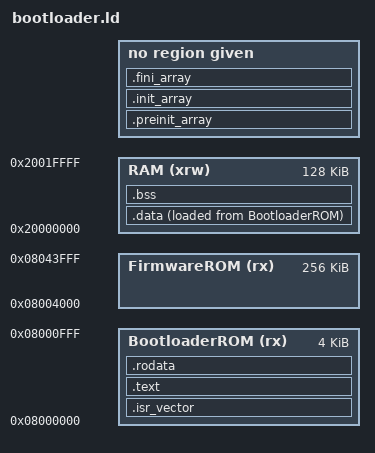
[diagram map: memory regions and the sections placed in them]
ENTRY(Reset_Handler)
_estack = ORIGIN(RAM) + LENGTH(RAM);

MEMORY
{
  RAM            (xrw) : ORIGIN = 0x20000000,  LENGTH = 128K
  BootloaderROM  (rx)  : ORIGIN = 0x8000000,   LENGTH = 4K
  FirmwareROM    (rx)  : ORIGIN = 0x8004000,   LENGTH = 256K
}

_sfirmware = ORIGIN(FirmwareROM);

SECTIONS
{
  .isr_vector :
  {
    . = ALIGN(4);
    KEEP(*(.isr_vector))
    . = ALIGN(4);
  } >BootloaderROM

  .text :
  {
    . = ALIGN(4);
    *(.text)
    *(.text*)

    KEEP (*(.init))
    KEEP (*(.fini))

    . = ALIGN(4);
    _etext = .;
  } >BootloaderROM

  .rodata :
  {
    . = ALIGN(4);

    *(.rodata)
    *(.rodata*)

    . = ALIGN(4);
  } >BootloaderROM


  .preinit_array     :
  {
    . = ALIGN(4);
    PROVIDE_HIDDEN (__preinit_array_start = .);
    KEEP (*(.preinit_array*))
    PROVIDE_HIDDEN (__preinit_array_end = .);
    . = ALIGN(4);
  } >FLASH

  .init_array :
  {
    . = ALIGN(4);
    PROVIDE_HIDDEN (__init_array_start = .);
    KEEP (*(SORT(.init_array.*)))
    KEEP (*(.init_array*))
    PROVIDE_HIDDEN (__init_array_end = .);
    . = ALIGN(4);
  } >FLASH

  .fini_array :
  {
    . = ALIGN(4);
    PROVIDE_HIDDEN (__fini_array_start = .);
    KEEP (*(SORT(.fini_array.*)))
    KEEP (*(.fini_array*))
    PROVIDE_HIDDEN (__fini_array_end = .);
    . = ALIGN(4);
  } >FLASH

  _sidata = LOADADDR(.data);
  .data :
  {
    . = ALIGN(4);
    _sdata = .;

    *(.data)
    *(.data*)

    . = ALIGN(4);
    _edata = .;

  } >RAM AT> BootloaderROM

  . = ALIGN(4);
  .bss :
  {
    _sbss = .;

    *(.bss)
    *(.bss*)
    *(COMMON)

    . = ALIGN(4);
    _ebss = .;
  } >RAM

  /DISCARD/ :
  {
    libc.a ( * )
    libm.a ( * )
    libgcc.a ( * )
  }
}
